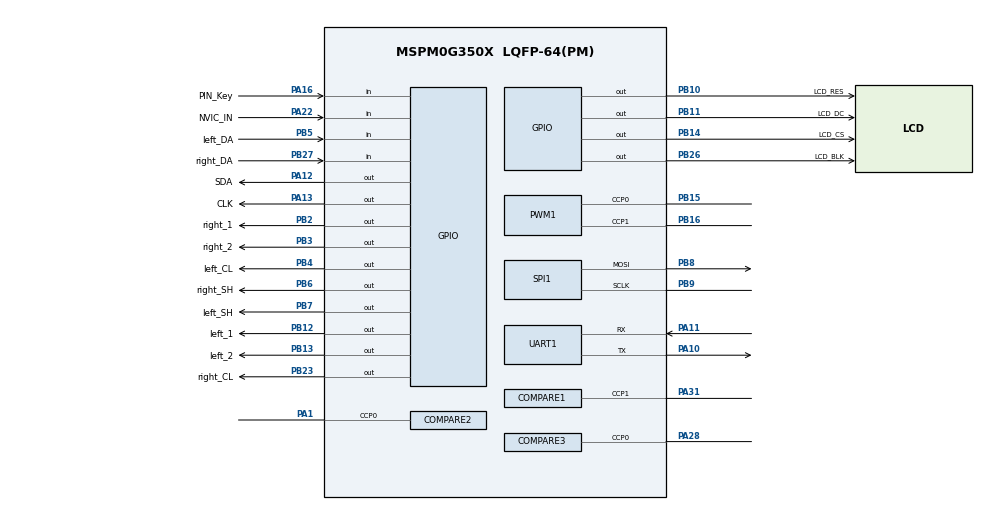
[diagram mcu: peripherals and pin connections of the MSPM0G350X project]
/**
 * @cliArgs --device "MSPM0G350X" --part "Default" --package "LQFP-64(PM)" --product "mspm0_sdk@2.04.00.06"
 * @versions {"tool":"1.21.1+3772"}
 */

/**
 * Import the modules used in this configuration.
 */
const COMPARE  = scripting.addModule("/ti/driverlib/COMPARE", {}, false);
const COMPARE1 = COMPARE.addInstance();
const COMPARE2 = COMPARE.addInstance();
const COMPARE3 = COMPARE.addInstance();
const COMPARE4 = COMPARE.addInstance();
const GPIO     = scripting.addModule("/ti/driverlib/GPIO", {}, false);
const GPIO1    = GPIO.addInstance();
const GPIO2    = GPIO.addInstance();
const GPIO3    = GPIO.addInstance();
const GPIO4    = GPIO.addInstance();
const GPIO5    = GPIO.addInstance();
const MATHACL  = scripting.addModule("/ti/driverlib/MATHACL");
const PWM      = scripting.addModule("/ti/driverlib/PWM", {}, false);
const PWM1     = PWM.addInstance();
const SPI      = scripting.addModule("/ti/driverlib/SPI", {}, false);
const SPI1     = SPI.addInstance();
const SYSCTL   = scripting.addModule("/ti/driverlib/SYSCTL");
const TIMER    = scripting.addModule("/ti/driverlib/TIMER", {}, false);
const TIMER1   = TIMER.addInstance();
const TIMER2   = TIMER.addInstance();
const UART     = scripting.addModule("/ti/driverlib/UART", {}, false);
const UART1    = UART.addInstance();

/**
 * Write custom configuration values to the imported modules.
 */
const divider2       = system.clockTree["HFCLK4MFPCLKDIV"];
divider2.divideValue = 10;

const divider9       = system.clockTree["UDIV"];
divider9.divideValue = 2;

const gate7  = system.clockTree["MFCLKGATE"];
gate7.enable = true;

const gate8  = system.clockTree["MFPCLKGATE"];
gate8.enable = true;

const multiplier2         = system.clockTree["PLL_QDIV"];
multiplier2.multiplyValue = 5;

const mux4       = system.clockTree["EXHFMUX"];
mux4.inputSelect = "EXHFMUX_XTAL";

const mux5       = system.clockTree["EXLFMUX"];
mux5.inputSelect = "EXLFMUX_XTAL";

const mux8       = system.clockTree["HSCLKMUX"];
mux8.inputSelect = "HSCLKMUX_SYSPLL0";

const mux10       = system.clockTree["MFPCLKMUX"];
mux10.inputSelect = "MFPCLKMUX_HFCLK";

const pinFunction4     = system.clockTree["HFXT"];
pinFunction4.enable    = true;
pinFunction4.inputFreq = 40;

const pinFunction6     = system.clockTree["LFXT"];
pinFunction6.inputFreq = 32.768;

COMPARE1.$name                          = "right_CAP_A";
COMPARE1.ccIndex                        = 1;
COMPARE1.timerPeriod                    = 60000;
COMPARE1.timerStartTimer                = true;
COMPARE1.compareMode                    = "EDGE_COUNT_UP";
COMPARE1.edgeDetection                  = "EDGE";
COMPARE1.inputFilter                    = true;
COMPARE1.filterPeriod                   = "PER_8";
COMPARE1.timerClkDiv                    = 2;
COMPARE1.peripheral.$assign             = "TIMG12";
COMPARE1.peripheral.ccp1Pin.$assign     = "PA31";
COMPARE1.ccp1PinConfig.$name            = "ti_driverlib_gpio_GPIOPinGeneric3";
COMPARE1.ccp1PinConfig.enableConfig     = true;
COMPARE1.ccp1PinConfig.internalResistor = "PULL_DOWN";

const Board = scripting.addModule("/ti/driverlib/Board", {}, false);

COMPARE2.$name                              = "right_CAP_B";
COMPARE2.timerStartTimer                    = true;
COMPARE2.timerPeriod                        = 60000;
COMPARE2.compareMode                        = "EDGE_COUNT_UP";
COMPARE2.edgeDetection                      = "EDGE";
COMPARE2.inputFilter                        = true;
COMPARE2.filterPeriod                       = "PER_8";
COMPARE2.timerClkDiv                        = 2;
COMPARE2.peripheral.$assign                 = "TIMG8";
COMPARE2.peripheral.ccp0Pin.$assign         = "PA1";
COMPARE2.ccp0PinConfig.hideOutputInversion  = scripting.forceWrite(false);
COMPARE2.ccp0PinConfig.onlyInternalResistor = scripting.forceWrite(false);
COMPARE2.ccp0PinConfig.passedPeripheralType = scripting.forceWrite("Digital");
COMPARE2.ccp0PinConfig.$name                = "ti_driverlib_gpio_GPIOPinGeneric6";
COMPARE2.ccp0PinConfig.enableConfig         = true;
COMPARE2.ccp0PinConfig.internalResistor     = "PULL_DOWN";

COMPARE3.$name                              = "left_CAP_A";
COMPARE3.timerStartTimer                    = true;
COMPARE3.compareMode                        = "EDGE_COUNT_UP";
COMPARE3.edgeDetection                      = "EDGE";
COMPARE3.timerPeriod                        = 60000;
COMPARE3.inputFilter                        = true;
COMPARE3.filterPeriod                       = "PER_8";
COMPARE3.timerClkDiv                        = 2;
COMPARE3.peripheral.ccp0Pin.$assign         = "PA28";
COMPARE3.ccp0PinConfig.hideOutputInversion  = scripting.forceWrite(false);
COMPARE3.ccp0PinConfig.onlyInternalResistor = scripting.forceWrite(false);
COMPARE3.ccp0PinConfig.passedPeripheralType = scripting.forceWrite("Digital");
COMPARE3.ccp0PinConfig.$name                = "ti_driverlib_gpio_GPIOPinGeneric9";
COMPARE3.ccp0PinConfig.enableConfig         = true;
COMPARE3.ccp0PinConfig.internalResistor     = "PULL_DOWN";

COMPARE4.$name                              = "left_CAP_B";
COMPARE4.timerStartTimer                    = true;
COMPARE4.edgeDetection                      = "EDGE";
COMPARE4.compareMode                        = "EDGE_COUNT_UP";
COMPARE4.timerPeriod                        = 60000;
COMPARE4.inputFilter                        = true;
COMPARE4.filterPeriod                       = "PER_8";
COMPARE4.timerClkDiv                        = 2;
COMPARE4.ccp0PinConfig.hideOutputInversion  = scripting.forceWrite(false);
COMPARE4.ccp0PinConfig.onlyInternalResistor = scripting.forceWrite(false);
COMPARE4.ccp0PinConfig.passedPeripheralType = scripting.forceWrite("Digital");
COMPARE4.ccp0PinConfig.$name                = "ti_driverlib_gpio_GPIOPinGeneric10";
COMPARE4.ccp0PinConfig.enableConfig         = true;
COMPARE4.ccp0PinConfig.internalResistor     = "PULL_DOWN";

GPIO1.$name                          = "LCD";
GPIO1.associatedPins.create(4);
GPIO1.associatedPins[0].$name        = "LCD_RES";
GPIO1.associatedPins[0].pin.$assign  = "PB10";
GPIO1.associatedPins[1].$name        = "LCD_DC";
GPIO1.associatedPins[1].initialValue = "SET";
GPIO1.associatedPins[1].pin.$assign  = "PB11";
GPIO1.associatedPins[2].$name        = "LCD_CS";
GPIO1.associatedPins[2].initialValue = "SET";
GPIO1.associatedPins[2].pin.$assign  = "PB14";
GPIO1.associatedPins[3].$name        = "LCD_BLK";
GPIO1.associatedPins[3].pin.$assign  = "PB26";

GPIO2.$name                          = "motor";
GPIO2.associatedPins.create(4);
GPIO2.associatedPins[0].$name        = "left_1";
GPIO2.associatedPins[0].initialValue = "SET";
GPIO2.associatedPins[0].pin.$assign  = "PB12";
GPIO2.associatedPins[1].$name        = "left_2";
GPIO2.associatedPins[1].initialValue = "SET";
GPIO2.associatedPins[1].pin.$assign  = "PB13";
GPIO2.associatedPins[2].$name        = "right_1";
GPIO2.associatedPins[2].initialValue = "SET";
GPIO2.associatedPins[2].ioStructure  = "SD";
GPIO2.associatedPins[2].pin.$assign  = "PB2";
GPIO2.associatedPins[3].$name        = "right_2";
GPIO2.associatedPins[3].initialValue = "SET";
GPIO2.associatedPins[3].ioStructure  = "SD";
GPIO2.associatedPins[3].pin.$assign  = "PB3";

GPIO3.$name                               = "MPU6050";
GPIO3.port                                = "PORTA";
GPIO3.associatedPins.create(3);
GPIO3.associatedPins[0].$name             = "CLK";
GPIO3.associatedPins[0].initialValue      = "SET";
GPIO3.associatedPins[0].pin.$assign       = "PA13";
GPIO3.associatedPins[1].$name             = "SDA";
GPIO3.associatedPins[1].initialValue      = "SET";
GPIO3.associatedPins[1].pin.$assign       = "PA12";
GPIO3.associatedPins[2].$name             = "NVIC_IN";
GPIO3.associatedPins[2].direction         = "INPUT";
GPIO3.associatedPins[2].interruptEn       = true;
GPIO3.associatedPins[2].interruptPriority = "1";
GPIO3.associatedPins[2].polarity          = "FALL";
GPIO3.associatedPins[2].pin.$assign       = "PA22";

GPIO4.$name                         = "xun_ji";
GPIO4.associatedPins.create(6);
GPIO4.associatedPins[0].$name       = "left_SH";
GPIO4.associatedPins[0].pin.$assign = "PB7";
GPIO4.associatedPins[1].$name       = "left_CL";
GPIO4.associatedPins[1].pin.$assign = "PB4";
GPIO4.associatedPins[2].$name       = "left_DA";
GPIO4.associatedPins[2].direction   = "INPUT";
GPIO4.associatedPins[2].pin.$assign = "PB5";
GPIO4.associatedPins[3].$name       = "right_SH";
GPIO4.associatedPins[3].pin.$assign = "PB6";
GPIO4.associatedPins[4].$name       = "right_CL";
GPIO4.associatedPins[4].pin.$assign = "PB23";
GPIO4.associatedPins[5].$name       = "right_DA";
GPIO4.associatedPins[5].direction   = "INPUT";
GPIO4.associatedPins[5].pin.$assign = "PB27";

GPIO5.$name                         = "Key_Munber";
GPIO5.associatedPins[0].$name       = "PIN_Key";
GPIO5.associatedPins[0].direction   = "INPUT";
GPIO5.associatedPins[0].ioStructure = "SD";
GPIO5.associatedPins[0].inputFilter = "8_CYCLES";
GPIO5.associatedPins[0].pin.$assign = "PA16";

PWM1.$name                      = "PWM_0";
PWM1.clockDivider               = 4;
PWM1.peripheral.$assign         = "TIMG7";
PWM1.peripheral.ccp0Pin.$assign = "PB15";
PWM1.peripheral.ccp1Pin.$assign = "PB16";
PWM1.PWM_CHANNEL_0.$name        = "ti_driverlib_pwm_PWMTimerCC0";
PWM1.PWM_CHANNEL_0.invert       = true;
PWM1.PWM_CHANNEL_1.$name        = "ti_driverlib_pwm_PWMTimerCC1";
PWM1.PWM_CHANNEL_1.invert       = true;
PWM1.ccp0PinConfig.$name        = "ti_driverlib_gpio_GPIOPinGeneric4";
PWM1.ccp0PinConfig.enableConfig = true;
PWM1.ccp1PinConfig.$name        = "ti_driverlib_gpio_GPIOPinGeneric5";
PWM1.ccp1PinConfig.enableConfig = true;

SPI1.$name                              = "SPI_1";
SPI1.frameFormat                        = "MOTO3";
SPI1.peripheral.sclkPin.$assign         = "PB9";
SPI1.peripheral.mosiPin.$assign         = "PB8";
SPI1.sclkPinConfig.direction            = scripting.forceWrite("OUTPUT");
SPI1.sclkPinConfig.onlyInternalResistor = scripting.forceWrite(false);
SPI1.sclkPinConfig.passedPeripheralType = scripting.forceWrite("Digital");
SPI1.sclkPinConfig.$name                = "ti_driverlib_gpio_GPIOPinGeneric0";
SPI1.sclkPinConfig.enableConfig         = true;
SPI1.sclkPinConfig.internalResistor     = "PULL_UP";
SPI1.mosiPinConfig.direction            = scripting.forceWrite("OUTPUT");
SPI1.mosiPinConfig.hideOutputInversion  = scripting.forceWrite(false);
SPI1.mosiPinConfig.onlyInternalResistor = scripting.forceWrite(false);
SPI1.mosiPinConfig.passedPeripheralType = scripting.forceWrite("Digital");
SPI1.mosiPinConfig.$name                = "ti_driverlib_gpio_GPIOPinGeneric1";
SPI1.mosiPinConfig.enableConfig         = true;
SPI1.mosiPinConfig.internalResistor     = "PULL_UP";
SPI1.misoPinConfig.onlyInternalResistor = scripting.forceWrite(false);
SPI1.misoPinConfig.passedPeripheralType = scripting.forceWrite("Digital");
SPI1.misoPinConfig.$name                = "ti_driverlib_gpio_GPIOPinGeneric2";

SYSCTL.forceDefaultClkConfig = true;
SYSCTL.clockTreeEn           = true;

TIMER1.$name              = "TIMER_0";
TIMER1.timerStartTimer    = true;
TIMER1.timerMode          = "PERIODIC";
TIMER1.timerClkDiv        = 8;
TIMER1.timerClkPrescale   = 10;
TIMER1.interrupts         = ["ZERO"];
TIMER1.timerPeriod        = "2.5 ms";
TIMER1.interruptPriority  = "0";
TIMER1.peripheral.$assign = "TIMG6";

TIMER2.$name              = "TIMER_1";
TIMER2.timerMode          = "PERIODIC";
TIMER2.timerPeriod        = "5 ms";
TIMER2.timerClkDiv        = 8;
TIMER2.interrupts         = ["ZERO"];
TIMER2.interruptPriority  = "1";
TIMER2.timerStartTimer    = true;
TIMER2.peripheral.$assign = "TIMG0";

UART1.$name                    = "UART_0";
UART1.enabledInterrupts        = ["RX"];
UART1.targetBaudRate           = 115200;
UART1.interruptPriority        = "1";
UART1.peripheral.rxPin.$assign = "PA11";
UART1.peripheral.txPin.$assign = "PA10";
UART1.txPinConfig.$name        = "ti_driverlib_gpio_GPIOPinGeneric7";
UART1.txPinConfig.enableConfig = true;
UART1.rxPinConfig.$name        = "ti_driverlib_gpio_GPIOPinGeneric8";
UART1.rxPinConfig.enableConfig = true;

/**
 * Pinmux solution for unlocked pins/peripherals. This ensures that minor changes to the automatic solver in a future
 * version of the tool will not impact the pinmux you originally saw.  These lines can be completely deleted in order to
 * re-solve from scratch.
 */
pinFunction4.peripheral.$suggestSolution           = "SYSCTL";
pinFunction4.peripheral.hfxInPin.$suggestSolution  = "PA5";
pinFunction4.peripheral.hfxOutPin.$suggestSolution = "PA6";
Board.peripheral.$suggestSolution                  = "DEBUGSS";
Board.peripheral.swclkPin.$suggestSolution         = "PA20";
Board.peripheral.swdioPin.$suggestSolution         = "PA19";
COMPARE3.peripheral.$suggestSolution               = "TIMA1";
COMPARE4.peripheral.$suggestSolution               = "TIMA0";
COMPARE4.peripheral.ccp0Pin.$suggestSolution       = "PA0";
SPI1.peripheral.$suggestSolution                   = "SPI1";
SPI1.peripheral.misoPin.$suggestSolution           = "PB21";
UART1.peripheral.$suggestSolution                  = "UART0";
